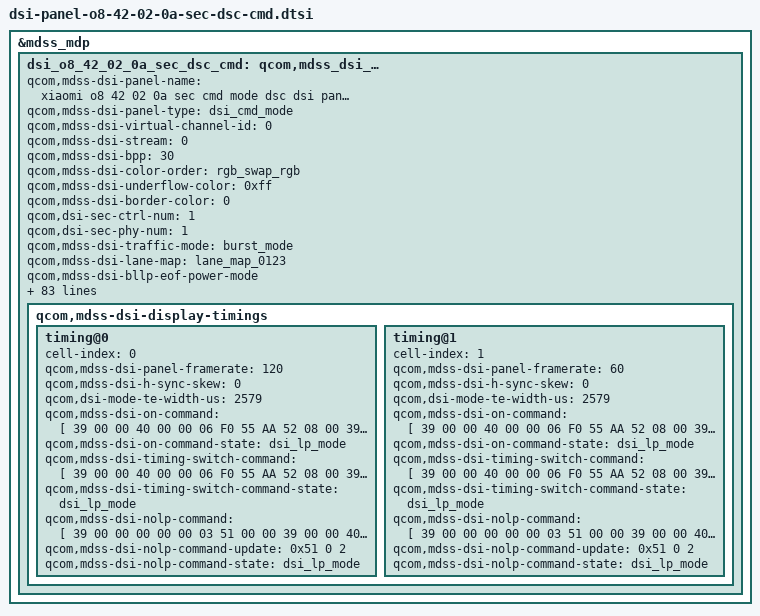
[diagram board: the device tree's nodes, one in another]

&mdss_mdp {
	dsi_o8_42_02_0a_sec_dsc_cmd: qcom,mdss_dsi_o8_42_02_0a_sec_dsc_cmd {
		qcom,mdss-dsi-panel-name = "xiaomi o8 42 02 0a sec cmd mode dsc dsi panel";
		qcom,mdss-dsi-panel-type = "dsi_cmd_mode";
		qcom,mdss-dsi-virtual-channel-id = <0>;
		qcom,mdss-dsi-stream = <0>;
		qcom,mdss-dsi-bpp = <30>;
		qcom,mdss-dsi-color-order = "rgb_swap_rgb";
		qcom,mdss-dsi-underflow-color = <0xff>;
		qcom,mdss-dsi-border-color = <0>;
		qcom,dsi-sec-ctrl-num = <1>;
		qcom,dsi-sec-phy-num = <1>;
		qcom,mdss-dsi-traffic-mode = "burst_mode";
		qcom,mdss-dsi-lane-map = "lane_map_0123";
		qcom,mdss-dsi-bllp-eof-power-mode;
		qcom,mdss-dsi-bllp-power-mode;
		qcom,mdss-dsi-lane-0-state;
		qcom,mdss-dsi-lane-1-state;
		//qcom,mdss-dsi-lane-2-state;
		//qcom,mdss-dsi-lane-3-state;
		qcom,mdss-dsi-dma-trigger = "trigger_sw";
		qcom,mdss-dsi-mdp-trigger = "none";
		qcom,mdss-dsi-reset-sequence = <1 1>, <0 1>, <1 10>;
		qcom,mdss-pan-physical-width-dimension = <668>;
		qcom,mdss-pan-physical-height-dimension = <769>;
		qcom,mdss-dsi-te-pin-select = <1>;
		qcom,mdss-dsi-wr-mem-start = <0x2c>;
		qcom,mdss-dsi-wr-mem-continue = <0x3c>;
		qcom,mdss-dsi-te-dcs-command = <1>;
		qcom,mdss-dsi-te-check-enable;
		qcom,mdss-dsi-te-using-te-pin;
		qcom,mdss-dsi-tx-eot-append;
		qcom,mdss-dsi-lp11-init;
		qcom,mdss-dsi-bl-inverted-dbv;
		qcom,bl-update-flag = "delay_until_first_frame";
		qcom,mdss-dsi-panel-hdr-enabled;
		qcom,mdss-dsi-panel-hdr-color-primaries = <14500 15500 32000
			17000 15500 30000 8000 3000>;
		qcom,mdss-dsi-panel-peak-brightness = <17000000>;
		qcom,mdss-dsi-panel-blackness-level = <17000000>;
		qcom,mdss-dsi-dma-schedule-line = <1>;
		qcom,mdss-dsi-dma-schedule-window = <50>;
		/* IRQF_ONESHOT | IRQF_TRIGGER_HEIGH */
		mi,esd-err-irq-gpio = <&tlmm 98 0x2004>;
		mi,esd-err-irq-gpio-flag = <0x2004>;
		//qcom,spr-pack-type = "pentile";
		mi,panel-id = <0x00004F38 0x5342020A>;
		mi,ddic-round-corner-enabled;
		qcom,mdss-disable-cesta-hw-sleep;

		mi,flat-need-sync-te;
		mi,flatmode-default-on-enabled;
		mi,flatmode-status-check-enabled;

		mi,mdss-dsi-panel-flatmode-status-command = [
			06 01 00 01 00 00 01 5F
		];
		mi,mdss-dsi-panel-flatmode-status-command-state = "dsi_hs_mode";
		mi,mdss-dsi-panel-flatmode-status-read-length = <1>;
		mi,mdss-dsi-panel-flatmode-on-status-value = <0x00>;

		mi,mdss-dsi-panel-wp-read-command = [06 01 00 01 00 00 01 A3];
		mi,mdss-dsi-panel-wp-read-command-state = "dsi_hs_mode";
		mi,mdss-dsi-panel-wp-read-length = <8>;

		mi,mdss-dsi-panel-cell-id-read-command = [06 01 00 01 00 00 01 B1];
		mi,mdss-dsi-panel-cell-id-read-pre-tx-command = [
			39 00 00 40 00 00 06 F0 55 AA 52 08 00
			15 00 00 40 00 00 02 EA 10
			39 00 00 00 00 00 06 F0 55 AA 52 00 00
		];
		mi,mdss-dsi-panel-cell-id-read-after-tx-command = [
			39 00 00 40 00 00 06 F0 55 AA 52 08 00
			15 00 00 00 00 00 02 EA 00
		];
		mi,mdss-dsi-panel-cell-id-read-pre-tx-command-state = "dsi_hs_mode";
		mi,mdss-dsi-panel-cell-id-read-after-tx-command-state = "dsi_hs_mode";
		mi,mdss-dsi-panel-cell-id-read-command-state = "dsi_hs_mode";
		mi,mdss-dsi-panel-cell-id-read-length = <13>;

		/* esd-check reg_read */
		//qcom,esd-check-enabled;
		//qcom,esd-aod-check-enabled;
		//mi,mdss-dsi-panel-status-check-interval = <1000>;
		//qcom,mdss-dsi-panel-status-check-mode = "reg_read";
		//mi,mdss-dsi-panel-status-offset-command = [39 00 00 00 00 00 03 FF 5A 82
		//					      39 00 00 00 00 00 02 65 01];
		//qcom,mdss-dsi-panel-status-command = [06 01 00 00 00 00 01 F9];
		//mi,mdss-dsi-panel-status-after-command = [39 00 00 00 00 00 03 FF 5A 00];
		//qcom,mdss-dsi-panel-status-command-state = "dsi_lp_mode";
		//mi,mdss-dsi-panel-status-offset-command-state = "dsi_lp_mode";
		//mi,mdss-dsi-panel-status-after-command-state = "dsi_lp_mode";
		//qcom,mdss-dsi-panel-status-value = <0x08>;
		//qcom,mdss-dsi-panel-status-read-length = <1>;
		mi,panel-on-dimming-delay = <120>;
		mi,max-brightness-clone = <16383>;
		mi,normal-max-brightness-clone = <8191>;
		mi,thermal-dimming-flag;
		mi,mdss-dsi-fac-bl-max-level = <12972>;
		mi,mdss-fac-brightness-max-level = <12972>;
		mi,doze-hbm-dbv-level = <808>;
		mi,doze-lbm-dbv-level = <56>;
		qcom,mdss-dsi-display-timings {
			timing@0 {
				#include "dsi-panel-o8-42-02-0a-sec-dsc-cmd-common.dtsi"
				cell-index = <0>;
				qcom,mdss-dsi-panel-framerate = <120>;
				qcom,mdss-dsi-h-sync-skew = <0>;
				qcom,dsi-mode-te-width-us = <2579>;
				qcom,mdss-dsi-on-command = [
					/*Remap DBV*/
					39 00 00 40 00 00 06 F0 55 AA 52 08 00
					39 00 00 40 00 00 02 6F DF
					39 00 00 40 00 00 06 B2 00 00 00 0F 00
					39 00 00 40 00 00 02 6F 02
					39 00 00 40 00 00 02 B2 3F
					39 00 00 40 00 00 02 6F 2B
					39 00 00 40 00 00 15 B2 00 00 00 00 3F FF 3F FF 3F FF 3F FF 3F FF 3F FF 3F FF 3F FF
					39 00 00 40 00 00 02 6F 3F
					39 00 00 40 00 00 15 B2 3F FF 3F FF 3F FF 3F FF 3F FF 3F FF 3F FF 3F FF 3F FF 3F FF
					39 00 00 40 00 00 02 6F 53
					39 00 00 40 00 00 15 B2 3F FF 3F FF 3F FF 3F FF 3F FF 3F FF 3F FF 3F FF 3F FF 3F FF
					39 00 00 40 00 00 02 6F 67
					39 00 00 40 00 00 0B B2 3F FF 3F FF 3F FF 3F FF 3F FF
					39 00 00 40 00 00 02 6F 34
					39 00 00 40 00 00 15 B3 00 0E 00 0F 3F FF 3F FF 3F FF 3F FF 3F FF 3F FF 3F FF 3F FF
					39 00 00 40 00 00 02 6F 48
					39 00 00 40 00 00 15 B3 3F FF 3F FF 3F FF 3F FF 3F FF 3F FF 3F FF 3F FF 3F FF 3F FF
					39 00 00 40 00 00 02 6F 5C
					39 00 00 40 00 00 15 B3 3F FF 3F FF 3F FF 3F FF 3F FF 3F FF 3F FF 3F FF 3F FF 3F FF
					39 00 00 40 00 00 02 6F 70
					39 00 00 00 00 00 09 B3 3F FF 3F FF 3F FF 3F FF
					/*ACL set*/
					39 00 00 40 00 00 06 F0 55 AA 52 08 00
					39 00 00 40 00 00 02 B0 00
					39 00 00 40 00 00 02 6F 17
					39 00 00 40 00 00 0B B0 32 AC 36 00 39 55 3C AA 3F FF
					39 00 00 40 00 00 02 6F 25
					39 00 00 40 00 00 0D B0 00 80 00 80 00 80 00 80 00 80 00 80
					39 00 00 40 00 00 02 6F 55
					39 00 00 40 00 00 07 B0 00 00 10 1E 2B 3B
					39 00 00 40 00 00 02 6F 6F
					39 00 00 00 00 00 07 B0 02 5C 04 B8 02 5C
					/*OD on*/
					39 00 00 40 00 00 06 F0 55 AA 52 08 08
					39 00 00 40 00 00 02 E0 21
					/*DBI on*/
					39 00 00 40 00 00 06 F0 55 AA 52 08 08
					39 00 00 40 00 00 02 C2 33
					39 00 00 40 00 00 06 F0 55 AA 52 08 04
					39 00 00 00 00 00 02 BB F3
					/* Esd config */
 					39 00 00 40 00 00 06 F0 55 AA 52 08 00
 					39 00 00 40 00 00 03 BE 47 45
 					39 00 00 40 00 00 02 6F 05
 					39 00 00 40 00 00 02 BE 28
 					39 00 00 40 00 00 02 6F 19
 					39 00 00 40 00 00 05 BE 10 91 00 AB
 					39 00 00 40 00 00 02 6F 0D
 					39 00 00 00 00 00 02 D8 42
					/* ACL ON */
					39 00 00 00 00 00 02 55 04
					/* Init code */
					39 00 00 40 00 00 05 FF AA 55 A5 80
					39 00 00 40 00 00 02 6F 47
					39 00 00 40 00 00 02 F2 20
					39 00 00 40 00 00 02 6F 05
					39 00 00 40 00 00 02 F8 59
					39 00 00 40 00 00 02 6F 21
					39 00 00 00 00 00 02 F8 59
					39 00 00 40 00 00 05 FF AA 55 A5 81
					39 00 00 40 00 00 02 6F 13
					39 00 00 00 00 00 02 F9 00
					39 00 00 40 00 00 05 FF AA 55 A5 80
					39 00 00 40 00 00 02 6F 2A
					39 00 00 00 00 00 02 F4 08
					39 00 00 40 00 00 05 FF AA 55 A5 82
					39 00 00 40 00 00 02 6F 09
					39 00 00 00 00 00 02 F2 FF
					39 00 00 40 00 00 06 F0 55 AA 52 08 01
					39 00 00 40 00 00 02 6F 06
					39 00 00 00 00 00 03 C5 0A 0A
					39 00 00 40 00 00 06 F0 55 AA 52 08 01
					39 00 00 00 00 00 02 E5 00
					39 00 00 40 00 00 06 F0 55 AA 52 08 01
					39 00 00 40 00 00 02 6F A2
					39 00 00 40 00 00 06 E7 FF FF FF FF FF
					39 00 00 40 00 00 02 6F 01
					39 00 00 40 00 00 02 E7 24
					39 00 00 40 00 00 02 6F 02
					39 00 00 40 00 00 02 E7 20
					39 00 00 40 00 00 02 6F 07
					39 00 00 40 00 00 02 E7 24
					39 00 00 40 00 00 02 6F 0C
					39 00 00 40 00 00 02 E7 18
					39 00 00 40 00 00 02 6F 11
					39 00 00 40 00 00 02 E7 0C
					39 00 00 40 00 00 02 6F B6
					39 00 00 40 00 00 09 E2 00 00 00 00 00 00 00 00
					39 00 00 40 00 00 02 6F BE
					39 00 00 40 00 00 11 E2 00 00 00 00 00 00 00 00 00 00 00 00 00 00 00 00
					39 00 00 40 00 00 02 6F CE
					39 00 00 40 00 00 09 E2 00 00 00 00 00 00 00 00
					39 00 00 40 00 00 02 6F D6
					39 00 00 40 00 00 11 E2 00 00 00 00 00 00 00 00 00 00 00 00 00 00 00 00
					39 00 00 40 00 00 06 F0 55 AA 52 08 02
					39 00 00 40 00 00 02 BE 13
					39 00 00 40 00 00 05 FF AA 55 A5 80
					39 00 00 40 00 00 02 6F 0A
					39 00 00 00 00 00 06 F6 70 70 70 70 70
					39 00 00 40 00 00 05 FF AA 55 A5 80
					39 00 00 40 00 00 02 6F 16
					39 00 00 40 00 00 03 F4 02 74
					39 00 00 40 00 00 05 FF AA 55 A5 80
					39 00 00 40 00 00 02 6F 32
					39 00 00 40 00 00 02 F9 00
					39 00 00 40 00 00 05 FF AA 55 A5 81
					39 00 00 40 00 00 02 6F 0D
					39 00 00 40 00 00 02 FB 80
					39 00 00 40 00 00 05 FF AA 55 A5 81
					39 00 00 40 00 00 02 6F 05
					39 00 00 40 00 00 03 FE 3C 3C
					39 00 00 40 00 00 02 6F 02
					39 00 00 40 00 00 02 F9 04
					39 00 00 40 00 00 02 6F 0C
					39 00 00 40 00 00 02 FD 08
					39 00 00 40 00 00 02 6F 10
					39 00 00 40 00 00 02 FB 40
					39 00 00 40 00 00 05 FF AA 55 A5 80
					39 00 00 40 00 00 02 6F 15
					39 00 00 00 00 00 03 F8 01 8D
					39 00 00 40 00 00 05 FF AA 55 A5 80
					39 00 00 40 00 00 02 6F 42
					39 00 00 40 00 00 02 F4 00
					39 00 00 40 00 00 02 6F 49
					39 00 00 40 00 00 02 F2 10
					39 00 00 40 00 00 02 17 30
					39 00 00 40 00 00 02 16 01
					39 00 00 40 00 00 05 2A 00 00 04 B7
					39 00 00 40 00 00 05 2B 00 00 05 6F
					/* AUTO OFF */
					39 00 00 40 00 00 06 F0 55 AA 52 08 00
					39 00 00 40 00 00 02 6F D9
					39 00 00 40 00 00 02 BA 04
					/* FIX TE ON */
					39 00 00 00 00 00 02 5A 00
					/* 120Hz */
					39 00 00 40 00 00 02 6F 03
					39 00 00 40 00 00 03 35 00 00
					39 00 00 40 00 00 02 2F 00
					/* Gir on */
					39 00 00 40 00 00 02 5F 00
					39 00 00 40 00 00 02 35 00
					39 00 00 40 00 00 03 51 00 00
					39 00 00 40 00 00 02 53 20
					/*VESA */
					39 00 00 40 00 00 03 90 03 43
					39 00 00 00 00 00 13 91 AB A8 00 0C C2 00 02 2F 01 30 00 08 08 BB 07 8E 10 F0
					39 00 00 40 00 00 02 6F 06
					39 00 00 40 00 00 02 6D 04
					39 00 00 00 00 00 02 26 00
					/* 109/138.8/Video Track 1.2G */
					39 00 00 40 00 00 06 F0 55 AA 52 08 01
					39 00 00 00 00 00 2A C3 DD 06 20 13 FF 00 06 20 13 FF 00 06 2A 22 06 41 1B 06 2A 22 06 41 1B 06 2A 22 06 41 1B 06 2A 22 06 41 1B 06 2A 22 06 41 1B
					/* Display On */
					05 00 00 00 78 00 01 11
					05 00 00 00 00 00 01 29
				];
				qcom,mdss-dsi-on-command-state = "dsi_lp_mode";
				qcom,mdss-dsi-timing-switch-command = [
					39 00 00 40 00 00 06 F0 55 AA 52 08 00
					/* AUTO OFF */
					39 00 00 40 00 00 02 6F D9
					39 00 00 40 00 00 02 BA 04
					/* Frequency Select 120Hz */
					39 00 00 40 00 00 02 5A 00
					39 00 00 40 00 00 02 6F 03
					39 00 00 40 00 00 03 35 00 00
					39 00 00 00 00 00 02 2F 00
				];
				qcom,mdss-dsi-timing-switch-command-state = "dsi_lp_mode";
				qcom,mdss-dsi-nolp-command = [
					39 00 00 00 00 00 03 51 00 00
					/* Aod Mode Off */
					39 00 00 40 00 00 02 38 00
					/* back to normal te */
					39 00 00 40 00 00 02 6F 03
					39 00 00 40 00 00 03 35 00 00
					39 00 00 00 00 00 02 2F 00
				];
				qcom,mdss-dsi-nolp-command-update = <0x51 0 2>;
				qcom,mdss-dsi-nolp-command-state = "dsi_lp_mode";
			};
			timing@1 {
				#include "dsi-panel-o8-42-02-0a-sec-dsc-cmd-common.dtsi"
				cell-index = <1>;
				qcom,mdss-dsi-panel-framerate = <60>;
				qcom,mdss-dsi-h-sync-skew = <0>;
				qcom,dsi-mode-te-width-us = <2579>;
				qcom,mdss-dsi-on-command = [
					/*Remap DBV*/
					39 00 00 40 00 00 06 F0 55 AA 52 08 00
					39 00 00 40 00 00 02 6F DF
					39 00 00 40 00 00 06 B2 00 00 00 0F 00
					39 00 00 40 00 00 02 6F 02
					39 00 00 40 00 00 02 B2 3F
					39 00 00 40 00 00 02 6F 2B
					39 00 00 40 00 00 15 B2 00 00 00 00 3F FF 3F FF 3F FF 3F FF 3F FF 3F FF 3F FF 3F FF
					39 00 00 40 00 00 02 6F 3F
					39 00 00 40 00 00 15 B2 3F FF 3F FF 3F FF 3F FF 3F FF 3F FF 3F FF 3F FF 3F FF 3F FF
					39 00 00 40 00 00 02 6F 53
					39 00 00 40 00 00 15 B2 3F FF 3F FF 3F FF 3F FF 3F FF 3F FF 3F FF 3F FF 3F FF 3F FF
					39 00 00 40 00 00 02 6F 67
					39 00 00 40 00 00 0B B2 3F FF 3F FF 3F FF 3F FF 3F FF
					39 00 00 40 00 00 02 6F 34
					39 00 00 40 00 00 15 B3 00 0E 00 0F 3F FF 3F FF 3F FF 3F FF 3F FF 3F FF 3F FF 3F FF
					39 00 00 40 00 00 02 6F 48
					39 00 00 40 00 00 15 B3 3F FF 3F FF 3F FF 3F FF 3F FF 3F FF 3F FF 3F FF 3F FF 3F FF
					39 00 00 40 00 00 02 6F 5C
					39 00 00 40 00 00 15 B3 3F FF 3F FF 3F FF 3F FF 3F FF 3F FF 3F FF 3F FF 3F FF 3F FF
					39 00 00 40 00 00 02 6F 70
					39 00 00 00 00 00 09 B3 3F FF 3F FF 3F FF 3F FF
					/*ACL set*/
					39 00 00 40 00 00 06 F0 55 AA 52 08 00
					39 00 00 40 00 00 02 B0 00
					39 00 00 40 00 00 02 6F 17
					39 00 00 40 00 00 0B B0 32 AC 36 00 39 55 3C AA 3F FF
					39 00 00 40 00 00 02 6F 25
					39 00 00 40 00 00 0D B0 00 80 00 80 00 80 00 80 00 80 00 80
					39 00 00 40 00 00 02 6F 55
					39 00 00 40 00 00 07 B0 00 00 10 1E 2B 3B
					39 00 00 40 00 00 02 6F 6F
					39 00 00 00 00 00 07 B0 02 5C 04 B8 02 5C
					/*OD on*/
					39 00 00 40 00 00 06 F0 55 AA 52 08 08
					39 00 00 40 00 00 02 E0 21
					/*DBI on*/
					39 00 00 40 00 00 06 F0 55 AA 52 08 08
					39 00 00 40 00 00 02 C2 33
					39 00 00 40 00 00 06 F0 55 AA 52 08 04
					39 00 00 00 00 00 02 BB F3
					/* Esd config */
 					39 00 00 40 00 00 06 F0 55 AA 52 08 00
 					39 00 00 40 00 00 03 BE 47 45
 					39 00 00 40 00 00 02 6F 05
 					39 00 00 40 00 00 02 BE 28
 					39 00 00 40 00 00 02 6F 19
 					39 00 00 40 00 00 05 BE 10 91 00 AB
 					39 00 00 40 00 00 02 6F 0D
 					39 00 00 00 00 00 02 D8 42
					/* ACL ON */
					39 00 00 00 00 00 02 55 04
					/* Init code */
					39 00 00 40 00 00 05 FF AA 55 A5 80
					39 00 00 40 00 00 02 6F 47
					39 00 00 40 00 00 02 F2 20
					39 00 00 40 00 00 02 6F 05
					39 00 00 40 00 00 02 F8 59
					39 00 00 40 00 00 02 6F 21
					39 00 00 00 00 00 02 F8 59
					39 00 00 40 00 00 05 FF AA 55 A5 81
					39 00 00 40 00 00 02 6F 13
					39 00 00 00 00 00 02 F9 00
					39 00 00 40 00 00 05 FF AA 55 A5 80
					39 00 00 40 00 00 02 6F 2A
					39 00 00 00 00 00 02 F4 08
					39 00 00 40 00 00 05 FF AA 55 A5 82
					39 00 00 40 00 00 02 6F 09
					39 00 00 00 00 00 02 F2 FF
					39 00 00 40 00 00 06 F0 55 AA 52 08 01
					39 00 00 40 00 00 02 6F 06
					39 00 00 00 00 00 03 C5 0A 0A
					39 00 00 40 00 00 06 F0 55 AA 52 08 01
					39 00 00 00 00 00 02 E5 00
					39 00 00 40 00 00 06 F0 55 AA 52 08 01
					39 00 00 40 00 00 02 6F A2
					39 00 00 40 00 00 06 E7 FF FF FF FF FF
					39 00 00 40 00 00 02 6F 01
					39 00 00 40 00 00 02 E7 24
					39 00 00 40 00 00 02 6F 02
					39 00 00 40 00 00 02 E7 20
					39 00 00 40 00 00 02 6F 07
					39 00 00 40 00 00 02 E7 24
					39 00 00 40 00 00 02 6F 0C
					39 00 00 40 00 00 02 E7 18
					39 00 00 40 00 00 02 6F 11
					39 00 00 40 00 00 02 E7 0C
					39 00 00 40 00 00 02 6F B6
					39 00 00 40 00 00 09 E2 00 00 00 00 00 00 00 00
					39 00 00 40 00 00 02 6F BE
					39 00 00 40 00 00 11 E2 00 00 00 00 00 00 00 00 00 00 00 00 00 00 00 00
					39 00 00 40 00 00 02 6F CE
					39 00 00 40 00 00 09 E2 00 00 00 00 00 00 00 00
					39 00 00 40 00 00 02 6F D6
					39 00 00 40 00 00 11 E2 00 00 00 00 00 00 00 00 00 00 00 00 00 00 00 00
					39 00 00 40 00 00 06 F0 55 AA 52 08 02
					39 00 00 40 00 00 02 BE 13
					39 00 00 40 00 00 05 FF AA 55 A5 80
					39 00 00 40 00 00 02 6F 0A
					39 00 00 00 00 00 06 F6 70 70 70 70 70
					39 00 00 40 00 00 05 FF AA 55 A5 80
					39 00 00 40 00 00 02 6F 16
					39 00 00 40 00 00 03 F4 02 74
					39 00 00 40 00 00 05 FF AA 55 A5 80
					39 00 00 40 00 00 02 6F 32
					39 00 00 40 00 00 02 F9 00
					39 00 00 40 00 00 05 FF AA 55 A5 81
					39 00 00 40 00 00 02 6F 0D
					39 00 00 40 00 00 02 FB 80
					39 00 00 40 00 00 05 FF AA 55 A5 81
					39 00 00 40 00 00 02 6F 05
					39 00 00 40 00 00 03 FE 3C 3C
					39 00 00 40 00 00 02 6F 02
					39 00 00 40 00 00 02 F9 04
					39 00 00 40 00 00 02 6F 0C
					39 00 00 40 00 00 02 FD 08
					39 00 00 40 00 00 02 6F 10
					39 00 00 40 00 00 02 FB 40
					39 00 00 40 00 00 05 FF AA 55 A5 80
					39 00 00 40 00 00 02 6F 15
					39 00 00 00 00 00 03 F8 01 8D
					39 00 00 40 00 00 05 FF AA 55 A5 80
					39 00 00 40 00 00 02 6F 42
					39 00 00 40 00 00 02 F4 00
					39 00 00 40 00 00 02 6F 49
					39 00 00 40 00 00 02 F2 10
					39 00 00 40 00 00 02 17 30
					39 00 00 40 00 00 02 16 01
					39 00 00 40 00 00 05 2A 00 00 04 B7
					39 00 00 40 00 00 05 2B 00 00 05 6F
					/* AUTO OFF */
					39 00 00 40 00 00 06 F0 55 AA 52 08 00
					39 00 00 40 00 00 02 6F D9
					39 00 00 40 00 00 02 BA 04
					/*backlight off the back fun*/
					39 00 00 40 00 00 04 8C 02 00 11
					/* FIX TE ON */
					39 00 00 00 00 00 02 5A 00
					/* 60Hz */
 					39 00 00 40 00 00 02 2F 30
 					39 00 00 40 00 00 02 5A 00
					39 00 00 40 00 00 02 6F 03
					39 00 00 40 00 00 03 35 00 01
 					39 00 00 00 00 00 02 6D 00
					/* Gir on */
					39 00 00 40 00 00 02 5F 00
					39 00 00 40 00 00 02 35 00
					39 00 00 40 00 00 03 51 00 00
					39 00 00 40 00 00 02 53 20
					/*VESA */
					39 00 00 40 00 00 03 90 03 43
					39 00 00 00 00 00 13 91 AB A8 00 0C C2 00 02 2F 01 30 00 08 08 BB 07 8E 10 F0
					39 00 00 40 00 00 02 6F 06
					39 00 00 40 00 00 02 6D 04
					39 00 00 00 00 00 02 26 00
					/* 109/138.8/Video Track 1.2G */
					39 00 00 40 00 00 06 F0 55 AA 52 08 01
					39 00 00 00 00 00 2A C3 DD 06 20 13 FF 00 06 20 13 FF 00 06 2A 22 06 41 1B 06 2A 22 06 41 1B 06 2A 22 06 41 1B 06 2A 22 06 41 1B 06 2A 22 06 41 1B
					/* Display On */
					05 00 00 00 78 00 01 11
					05 00 00 00 00 00 01 29
				];
				qcom,mdss-dsi-on-command-state = "dsi_lp_mode";
				qcom,mdss-dsi-timing-switch-command = [
					39 00 00 40 00 00 06 F0 55 AA 52 08 00
					/* AUTO OFF */
					39 00 00 40 00 00 02 6F D9
					39 00 00 40 00 00 02 BA 04
					/*backlight off the back fun*/
					39 00 00 40 00 00 04 8C 02 00 11
					/* Frequency Select 60Hz */
 					39 00 00 40 00 00 02 2F 30
 					39 00 00 40 00 00 02 5A 00
					39 00 00 40 00 00 02 6F 03
					39 00 00 40 00 00 03 35 00 01
 					39 00 00 00 00 00 02 6D 00
				];
				qcom,mdss-dsi-timing-switch-command-state = "dsi_lp_mode";
				qcom,mdss-dsi-nolp-command = [
					39 00 00 00 00 00 03 51 00 00
					/* Aod Mode Off */
					39 00 00 40 00 00 02 38 00
					/* back to normal te */
					39 00 00 40 00 00 02 6F 03
					39 00 00 00 00 00 03 35 00 01
				];
				qcom,mdss-dsi-nolp-command-update = <0x51 0 2>;
				qcom,mdss-dsi-nolp-command-state = "dsi_lp_mode";
			};
		};
	};
};
&dsi_o8_42_02_0a_sec_dsc_cmd {
	qcom,panel-sec-supply-entries = <&dsi_panel_pwr_supply_sec_O8>;
	qcom,mdss-dsi-sec-bl-pmic-control-type = "bl_ctrl_dcs";
	qcom,mdss-dsi-bl-min-level = <15>;
	qcom,mdss-dsi-bl-max-level = <16383>;
	qcom,bl-dsc-cmd-state = "dsi_lp_mode";
	qcom,mdss-brightness-max-level = <16383>;
	qcom,mdss-brightness-init-level = <307>;
    qcom,platform-sec-reset-gpio = <&tlmm 110 0>;
	//mi,panel-build-id-read-needed;
	//mi,panel-build-id-read-length = <1>;
	//mi,mdss-dsi-panel-build-id-read-command = [06 01 00 01 00 00 01 5B];
	//mi,mdss-dsi-panel-build-id-read-command-state = "dsi_hs_mode";
	mi,disable-ic-dimming-flag;
	qcom,mdss-dsi-panel-vsync-delay;
    qcom,ulps-enabled;
    qcom,dsi-select-sec-clocks = "pll_byte_clk1", "pll_dsi_clk1";
    qcom,mdss-dsi-clk-strength = <0xFF>;
};
